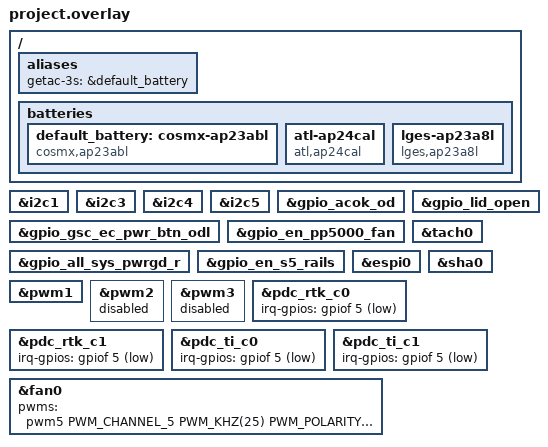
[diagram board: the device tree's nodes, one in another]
/* Copyright 2025 The ChromiumOS Authors
 * Use of this source code is governed by a BSD-style license that can be
 * found in the LICENSE file.
 */

/* ocelot program common DTS includes */

#include <cros/integrated_fwid.dtsi>

/* ocelotrvp-ite project DTS includes */

#include "binman.dtsi"
#include "gpios.dtsi"
#include "power_signals.dtsi"

/*
 * Map I2C buses to common names
 */

i2c_port_pd1: &i2c1 {};
i2c_port_pd2: &i2c3 {};
i2c_port_charger: &i2c4 {};
i2c_port_ish: &i2c5 {};

/*
 * Map GPIOs used for interrupts to common names
 */

gpio_acok: &gpio_acok_od {};
//gpio_dc_jack_present: &gpio_std_adp_prsnt_r {};
gpio_lid: &gpio_lid_open {};
gpio_pwrbtn: &gpio_gsc_ec_pwr_btn_odl {};
//gpio_voldn: &gpio_ec_voldn_btn_odl {};
//gpio_volup: &gpio_ec_volup_btn_odl {};
gpio_fan_control: &gpio_en_pp5000_fan {};
gpio_all_sys_pwr_good: &gpio_all_sys_pwrgd_r {};
gpio_temp_sensor_power_good: &gpio_en_s5_rails {};

/* Power sequencing */
//gpio_ec_pch_wake_odl: &gpio_smc_wake_sci_n_r {};
//cse_early_rec_sw: &gpio_c_mecc_cse_early_sw_r{};

/* Map tachometers to common names */
tach_fan0: &tach0 {};

#include "adc.dtsi"
#include "console.dtsi"
#include "fan.dtsi"
#include "hibernate.dtsi"
#include "usba.dtsi"
#include "i2c.dtsi"
#include "keyboard.dtsi"
#include "usb_typec.dtsi"
#include "interrupts.dtsi"
#include "led_pins.dtsi"
#include "led_policy.dtsi"
#include "pwm.dtsi"

#include "../rvp_temp_sensors.dtsi"

/ {
	aliases {
		getac-3s = &default_battery; // TODO
	};

	batteries {
		default_battery: cosmx-ap23abl {
			compatible = "cosmx,ap23abl", "battery-smart";
		};
		atl-ap24cal {
			compatible = "atl,ap24cal", "battery-smart";
		};
		lges-ap23a8l {
			compatible = "lges,ap23a8l", "battery-smart";
		};
	};
};

/* ocelotrvp-ite overrides follow... */

&espi0 {
	status = "okay";
};

&sha0 {
	status = "okay";
};

&pwm1 {
	status = "okay";
};
&pwm2 {
	status = "disabled";
};
&pwm3 {
	status = "disabled";
};

/* Update board-specific references  */

&pdc_rtk_c0 {
	irq-gpios = <&gpiof 5 GPIO_ACTIVE_LOW>;
};

&pdc_rtk_c1 {
	irq-gpios = <&gpiof 5 GPIO_ACTIVE_LOW>;
};

&pdc_ti_c0 {
	irq-gpios = <&gpiof 5 GPIO_ACTIVE_LOW>;
};

&pdc_ti_c1 {
	irq-gpios = <&gpiof 5 GPIO_ACTIVE_LOW>;
};

&fan0 {
	pwms = <&pwm5 PWM_CHANNEL_5 PWM_KHZ(25) PWM_POLARITY_NORMAL>;
};

